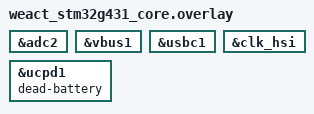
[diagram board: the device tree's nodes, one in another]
/*
 * Copyright (c) 2023 Andreas Sandberg
 *
 * SPDX-License-Identifier: Apache-2.0
 *
 */

#include <dt-bindings/usb-c/pd.h>

&adc2 {
	status = "okay";
};

&vbus1 {
	status = "okay";
};

&usbc1 {
	status = "okay";
};

&clk_hsi {
	/* The HSI is used by ucpd1 */
	status = "okay";
};

&ucpd1 {
	status = "okay";
	dead-battery;
};
